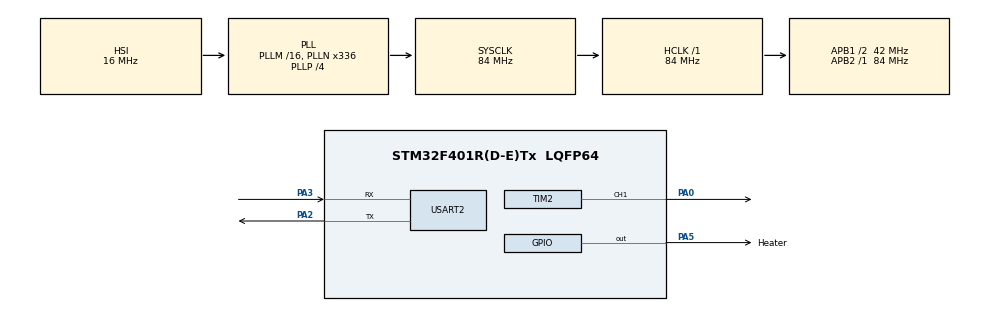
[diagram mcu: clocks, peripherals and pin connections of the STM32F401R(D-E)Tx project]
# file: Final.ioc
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ADC1.Channel-0\#ChannelRegularConversion=ADC_CHANNEL_TEMPSENSOR
ADC1.NbrOfConversionFlag=1
ADC1.Rank-0\#ChannelRegularConversion=1
ADC1.SamplingTime-0\#ChannelRegularConversion=ADC_SAMPLETIME_3CYCLES
ADC1.master=1
Mcu.Family=STM32F4
Mcu.Name=STM32F401R(D-E)Tx
Mcu.Package=LQFP64
NVIC.PriorityGroup=NVIC_PRIORITYGROUP_4
PA0-WKUP.Signal=S_TIM2_CH1_ETR
PA13.Mode=Serial_Wire
PA13.Signal=SYS_JTMS-SWDIO
PA14.Mode=Serial_Wire
PA14.Signal=SYS_JTCK-SWCLK
PA2.Mode=Asynchronous
PA2.Signal=USART2_TX
PA3.Mode=Asynchronous
PA3.Signal=USART2_RX
PA5.GPIO_Label=Heater
PA5.GPIO_PuPd=GPIO_NOPULL
PA5.Signal=GPIO_Output
PH0\ -\ OSC_IN.Mode=HSE-External-Oscillator
PH0\ -\ OSC_IN.Signal=RCC_OSC_IN
PH1\ -\ OSC_OUT.Mode=HSE-External-Oscillator
PH1\ -\ OSC_OUT.Signal=RCC_OSC_OUT
ProjectManager.HeapSize=0x200
ProjectManager.StackSize=0x400
ProjectManager.TargetToolchain=STM32CubeIDE
RCC.48MHZClocksFreq_Value=84000000
RCC.AHBFreq_Value=84000000
RCC.APB1CLKDivider=RCC_HCLK_DIV2
RCC.APB1Freq_Value=42000000
RCC.APB1TimFreq_Value=84000000
RCC.APB2Freq_Value=84000000
RCC.APB2TimFreq_Value=84000000
RCC.CortexFreq_Value=84000000
RCC.HCLKFreq_Value=84000000
RCC.HSE_VALUE=25000000
RCC.HSI_VALUE=16000000
RCC.LSE_VALUE=32768
RCC.PLLN=336
RCC.PLLP=RCC_PLLP_DIV4
RCC.SYSCLKFreq_VALUE=84000000
RCC.SYSCLKSource=RCC_SYSCLKSOURCE_PLLCLK
RCC.VCOOutputFreq_Value=336000000
SH.S_TIM2_CH1_ETR.0=TIM2_CH1,PWM Generation1 CH1
TIM2.Channel-PWM\ Generation1\ CH1=TIM_CHANNEL_1
TIM2.Period=8400-1
TIM2.Prescaler=200-1
USART2.VirtualMode=VM_ASYNC
VP_ADC1_TempSens_Input.Mode=IN-TempSens
VP_TIM2_VS_ClockSourceINT.Mode=Internal
board=custom

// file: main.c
/* USER CODE BEGIN Header */
/**
  ******************************************************************************
  * @file           : main.c
  * @brief          : Main program body
  ******************************************************************************
  * @attention
  *
  * Copyright (c) 2025 STMicroelectronics.
  * All rights reserved.
  *
  * This software is licensed under terms that can be found in the LICENSE file
  * in the root directory of this software component.
  * If no LICENSE file comes with this software, it is provided AS-IS.
  *
  ******************************************************************************
  */
/* USER CODE END Header */
#include "main.h"

ADC_HandleTypeDef hadc1;

TIM_HandleTypeDef htim2;

UART_HandleTypeDef huart2;

void SystemClock_Config(void);
static void MX_GPIO_Init(void);
static void MX_ADC1_Init(void);
static void MX_USART2_UART_Init(void);
static void MX_TIM2_Init(void);

void Set_Servo_Angle(TIM_HandleTypeDef *htim,uint32_t channel, uint8_t angle){
	uint32_t pulse_length = 210 + (angle*(1050-210)/180);
	__HAL_TIM_SET_COMPARE(htim,channel, pulse_length);
}

int _write(int file, char *ptr, int len) {
    HAL_UART_Transmit(&huart2, (uint8_t*) ptr, len, HAL_MAX_DELAY);
    return len;
}

#define TS_CAL1 *((uint16_t*)0x1FFF7A2C)  // Factory calibration at 30°C
#define TS_CAL2 *((uint16_t*)0x1FFF7A2E)  // Factory calibration at 110°C

int main(void)
{

  /* MCU Configuration--------------------------------------------------------*/

  /* Reset of all peripherals, Initializes the Flash interface and the Systick. */
  HAL_Init();

  /* Configure the system clock */
  SystemClock_Config();

  /* Initialize all configured peripherals */
  MX_GPIO_Init();
  MX_ADC1_Init();
  MX_USART2_UART_Init();
  MX_TIM2_Init();
  /* USER CODE BEGIN 2 */
  HAL_TIM_PWM_Start(&htim2, TIM_CHANNEL_1);
  char rx_buffer[6] = {0};

  /* USER CODE END 2 */

  /* Infinite loop */
  while (1)
  {

	  //RETREIVE TEMPERATURE VALUE:
	  uint32_t adcValue;
	  float temperature;
	  char msg[50];

	  // Start ADC conversion
	  HAL_ADC_Start(&hadc1);
	  HAL_ADC_PollForConversion(&hadc1, HAL_MAX_DELAY);
	  adcValue = HAL_ADC_GetValue(&hadc1);
	  HAL_ADC_Stop(&hadc1);

	  // Convert ADC value to temperature (refer to datasheet for constants)
	  float V25 = 0.76; // Typical voltage at 25°C
	  float Avg_Slope = 2.5 / 1000; // mV/°C
	  float Vref = 3.0; // Reference voltage

	  float Vsense = (adcValue * 3.0) / 4096.0;

	  temperature = ((Vsense - (TS_CAL1 * 3.0 / 4096.0)) * (110.0 - 30.0)) /
					((TS_CAL2 - TS_CAL1) * 3.0 / 4096.0) + 30.0;

	  temperature = temperature - 9.0; //MANUAL ADJUSTMENT

	  //TRIGGER HEATER FROM TEMPERATURE:
	  if (temperature < 20.5) { //20.5
		HAL_GPIO_WritePin(GPIOA, GPIO_PIN_5, GPIO_PIN_RESET);
		// Turn ON heating pad ON THE NUCLEO IT SHOULD BE PIN D13, turns on pad by stopping voltage fed through MOSFET
	  } else {

		  HAL_GPIO_WritePin(GPIOA, GPIO_PIN_5, GPIO_PIN_SET);
		  // Turn OFF heating pad (turn on voltage through pin)
	  }

	  // Print temperature via UART
	  //sprintf(msg, "Temperature: %.2f°C\r\n", temperature);
	  //sprintf(msg, "Temperature: %.2f°C | Heating: %s\r\n", temperature,
		//	  (temperature < 20.5) ? "ON" : "OFF");
	  //printf("%s", msg);

	  //TRIGGER MOTOR FROM PYTHON COMMUNICATION:
	  if (HAL_UART_Receive(&huart2, (uint8_t*)rx_buffer, 5, 1000) == HAL_OK)
	  {
		  if (temperature > 0) {
			  rx_buffer[5] = '\0';  // Null-terminate safely
			  printf("Received: %s\r\n", rx_buffer);  // Debug print
			  if (strncmp(rx_buffer, "START", 5) == 0) {
				  // Turn ON
				  for (uint8_t angle=60; angle<=115; angle+=3){
						  Set_Servo_Angle(&htim2, TIM_CHANNEL_1,angle);
						  HAL_Delay(100);
					  }
				  for (uint8_t angle=115; angle>60; angle-=3){
						  Set_Servo_Angle(&htim2, TIM_CHANNEL_1,angle);
						  HAL_Delay(100);
					  }
			  }
			  else if (strncmp(rx_buffer, "STOPP", 5) == 0) {
				  // Turn OFF
				  //DO NOTHING
			  }
			  memset(rx_buffer, 0, sizeof(rx_buffer));  // Clear for next use
		  }
	  }

	  //HAL_Delay(500);

  }
}

void SystemClock_Config(void)
{
  RCC_OscInitTypeDef RCC_OscInitStruct = {0};
  RCC_ClkInitTypeDef RCC_ClkInitStruct = {0};

  /** Configure the main internal regulator output voltage
  */
  __HAL_RCC_PWR_CLK_ENABLE();
  __HAL_PWR_VOLTAGESCALING_CONFIG(PWR_REGULATOR_VOLTAGE_SCALE2);

  /** Initializes the RCC Oscillators according to the specified parameters
  * in the RCC_OscInitTypeDef structure.
  */
  RCC_OscInitStruct.OscillatorType = RCC_OSCILLATORTYPE_HSI;
  RCC_OscInitStruct.HSIState = RCC_HSI_ON;
  RCC_OscInitStruct.HSICalibrationValue = RCC_HSICALIBRATION_DEFAULT;
  RCC_OscInitStruct.PLL.PLLState = RCC_PLL_ON;
  RCC_OscInitStruct.PLL.PLLSource = RCC_PLLSOURCE_HSI;
  RCC_OscInitStruct.PLL.PLLM = 16;
  RCC_OscInitStruct.PLL.PLLN = 336;
  RCC_OscInitStruct.PLL.PLLP = RCC_PLLP_DIV4;
  RCC_OscInitStruct.PLL.PLLQ = 4;
  if (HAL_RCC_OscConfig(&RCC_OscInitStruct) != HAL_OK)
  {
    Error_Handler();
  }

  /** Initializes the CPU, AHB and APB buses clocks
  */
  RCC_ClkInitStruct.ClockType = RCC_CLOCKTYPE_HCLK|RCC_CLOCKTYPE_SYSCLK
                              |RCC_CLOCKTYPE_PCLK1|RCC_CLOCKTYPE_PCLK2;
  RCC_ClkInitStruct.SYSCLKSource = RCC_SYSCLKSOURCE_PLLCLK;
  RCC_ClkInitStruct.AHBCLKDivider = RCC_SYSCLK_DIV1;
  RCC_ClkInitStruct.APB1CLKDivider = RCC_HCLK_DIV2;
  RCC_ClkInitStruct.APB2CLKDivider = RCC_HCLK_DIV1;

  if (HAL_RCC_ClockConfig(&RCC_ClkInitStruct, FLASH_LATENCY_2) != HAL_OK)
  {
    Error_Handler();
  }
}

static void MX_ADC1_Init(void)
{

  ADC_ChannelConfTypeDef sConfig = {0};

  /** Configure the global features of the ADC (Clock, Resolution, Data Alignment and number of conversion)
  */
  hadc1.Instance = ADC1;
  hadc1.Init.ClockPrescaler = ADC_CLOCK_SYNC_PCLK_DIV4;
  hadc1.Init.Resolution = ADC_RESOLUTION_12B;
  hadc1.Init.ScanConvMode = DISABLE;
  hadc1.Init.ContinuousConvMode = DISABLE;
  hadc1.Init.DiscontinuousConvMode = DISABLE;
  hadc1.Init.ExternalTrigConvEdge = ADC_EXTERNALTRIGCONVEDGE_NONE;
  hadc1.Init.ExternalTrigConv = ADC_SOFTWARE_START;
  hadc1.Init.DataAlign = ADC_DATAALIGN_RIGHT;
  hadc1.Init.NbrOfConversion = 1;
  hadc1.Init.DMAContinuousRequests = DISABLE;
  hadc1.Init.EOCSelection = ADC_EOC_SINGLE_CONV;
  if (HAL_ADC_Init(&hadc1) != HAL_OK)
  {
    Error_Handler();
  }

  /** Configure for the selected ADC regular channel its corresponding rank in the sequencer and its sample time.
  */
  sConfig.Channel = ADC_CHANNEL_TEMPSENSOR;
  sConfig.Rank = 1;
  sConfig.SamplingTime = ADC_SAMPLETIME_3CYCLES;
  if (HAL_ADC_ConfigChannel(&hadc1, &sConfig) != HAL_OK)
  {
    Error_Handler();
  }

}

static void MX_TIM2_Init(void)
{

  TIM_ClockConfigTypeDef sClockSourceConfig = {0};
  TIM_MasterConfigTypeDef sMasterConfig = {0};
  TIM_OC_InitTypeDef sConfigOC = {0};

  htim2.Instance = TIM2;
  htim2.Init.Prescaler = 200-1;
  htim2.Init.CounterMode = TIM_COUNTERMODE_UP;
  htim2.Init.Period = 8400-1;
  htim2.Init.ClockDivision = TIM_CLOCKDIVISION_DIV1;
  htim2.Init.AutoReloadPreload = TIM_AUTORELOAD_PRELOAD_DISABLE;
  if (HAL_TIM_Base_Init(&htim2) != HAL_OK)
  {
    Error_Handler();
  }
  sClockSourceConfig.ClockSource = TIM_CLOCKSOURCE_INTERNAL;
  if (HAL_TIM_ConfigClockSource(&htim2, &sClockSourceConfig) != HAL_OK)
  {
    Error_Handler();
  }
  if (HAL_TIM_PWM_Init(&htim2) != HAL_OK)
  {
    Error_Handler();
  }
  sMasterConfig.MasterOutputTrigger = TIM_TRGO_RESET;
  sMasterConfig.MasterSlaveMode = TIM_MASTERSLAVEMODE_DISABLE;
  if (HAL_TIMEx_MasterConfigSynchronization(&htim2, &sMasterConfig) != HAL_OK)
  {
    Error_Handler();
  }
  sConfigOC.OCMode = TIM_OCMODE_PWM1;
  sConfigOC.Pulse = 0;
  sConfigOC.OCPolarity = TIM_OCPOLARITY_HIGH;
  sConfigOC.OCFastMode = TIM_OCFAST_DISABLE;
  if (HAL_TIM_PWM_ConfigChannel(&htim2, &sConfigOC, TIM_CHANNEL_1) != HAL_OK)
  {
    Error_Handler();
  }
  HAL_TIM_MspPostInit(&htim2);

}

static void MX_USART2_UART_Init(void)
{

  huart2.Instance = USART2;
  huart2.Init.BaudRate = 115200;
  huart2.Init.WordLength = UART_WORDLENGTH_8B;
  huart2.Init.StopBits = UART_STOPBITS_1;
  huart2.Init.Parity = UART_PARITY_NONE;
  huart2.Init.Mode = UART_MODE_TX_RX;
  huart2.Init.HwFlowCtl = UART_HWCONTROL_NONE;
  huart2.Init.OverSampling = UART_OVERSAMPLING_16;
  if (HAL_UART_Init(&huart2) != HAL_OK)
  {
    Error_Handler();
  }

}

static void MX_GPIO_Init(void)
{
  GPIO_InitTypeDef GPIO_InitStruct = {0};

  /* GPIO Ports Clock Enable */
  __HAL_RCC_GPIOH_CLK_ENABLE();
  __HAL_RCC_GPIOA_CLK_ENABLE();

  /*Configure GPIO pin Output Level */
  HAL_GPIO_WritePin(Heater_GPIO_Port, Heater_Pin, GPIO_PIN_RESET);

  /*Configure GPIO pin : Heater_Pin */
  GPIO_InitStruct.Pin = Heater_Pin;
  GPIO_InitStruct.Mode = GPIO_MODE_OUTPUT_PP;
  GPIO_InitStruct.Pull = GPIO_NOPULL;
  GPIO_InitStruct.Speed = GPIO_SPEED_FREQ_LOW;
  HAL_GPIO_Init(Heater_GPIO_Port, &GPIO_InitStruct);

  __HAL_RCC_GPIOA_CLK_ENABLE();

  // Initially turn off heating pad
  HAL_GPIO_WritePin(GPIOA, GPIO_PIN_5, GPIO_PIN_RESET);

}

void Error_Handler(void)
{
  __disable_irq();
  while (1)
  {
  }
}
